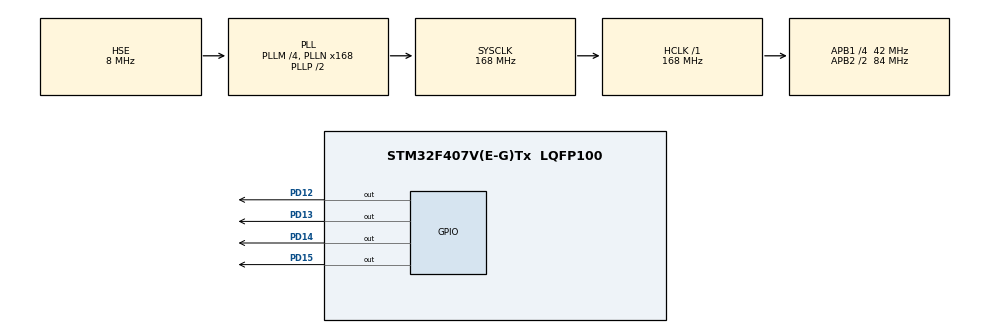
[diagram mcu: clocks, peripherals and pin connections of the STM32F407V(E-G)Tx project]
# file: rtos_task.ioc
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FREERTOS.INCLUDE_vTaskDelayUntil=1
FREERTOS.Tasks01=defaultTask,0,128,StartDefaultTask,Default,NULL,Dynamic,NULL,NULL
FREERTOS.configUSE_NEWLIB_REENTRANT=1
Mcu.Family=STM32F4
Mcu.Name=STM32F407V(E-G)Tx
Mcu.Package=LQFP100
NVIC.PriorityGroup=NVIC_PRIORITYGROUP_4
NVIC.TIM1_UP_TIM10_IRQn=true\:15\:0\:false\:false\:true\:false\:false\:true
NVIC.TimeBase=TIM1_UP_TIM10_IRQn
NVIC.TimeBaseIP=TIM1
PD12.Signal=GPIO_Output
PD13.Signal=GPIO_Output
PD14.Signal=GPIO_Output
PD15.Signal=GPIO_Output
PH0-OSC_IN.Mode=HSE-External-Oscillator
PH0-OSC_IN.Signal=RCC_OSC_IN
PH1-OSC_OUT.Mode=HSE-External-Oscillator
PH1-OSC_OUT.Signal=RCC_OSC_OUT
ProjectManager.HeapSize=0x200
ProjectManager.StackSize=0x400
ProjectManager.TargetToolchain=STM32CubeIDE
RCC.48MHZClocksFreq_Value=84000000
RCC.AHBFreq_Value=168000000
RCC.APB1CLKDivider=RCC_HCLK_DIV4
RCC.APB1Freq_Value=42000000
RCC.APB1TimFreq_Value=84000000
RCC.APB2CLKDivider=RCC_HCLK_DIV2
RCC.APB2Freq_Value=84000000
RCC.APB2TimFreq_Value=168000000
RCC.CortexFreq_Value=168000000
RCC.HCLKFreq_Value=168000000
RCC.HSE_VALUE=8000000
RCC.HSI_VALUE=16000000
RCC.LSE_VALUE=32768
RCC.PLLM=4
RCC.PLLN=168
RCC.PLLSourceVirtual=RCC_PLLSOURCE_HSE
RCC.SYSCLKFreq_VALUE=168000000
RCC.SYSCLKSource=RCC_SYSCLKSOURCE_PLLCLK
RCC.VCOOutputFreq_Value=336000000
VP_FREERTOS_VS_CMSIS_V1.Mode=CMSIS_V1
VP_SYS_VS_tim1.Mode=TIM1
board=custom

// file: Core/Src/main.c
/* USER CODE BEGIN Header */
/**
  ******************************************************************************
  * @file           : main.c
  * @brief          : Main program body
  ******************************************************************************
  * @attention
  *
  * <h2><center>&copy; Copyright (c) 2021 STMicroelectronics.
  * All rights reserved.</center></h2>
  *
  * This software component is licensed by ST under BSD 3-Clause license,
  * the "License"; You may not use this file except in compliance with the
  * License. You may obtain a copy of the License at:
  *                        opensource.org/licenses/BSD-3-Clause
  *
  ******************************************************************************
  */
/* USER CODE END Header */
#include "main.h"
#include "cmsis_os.h"

osThreadId defaultTaskHandle;

void SystemClock_Config(void);
static void MX_GPIO_Init(void);
void StartDefaultTask(void const * argument);

/* USER CODE BEGIN 0 */
int _write(int file,char*ptr, int len)
{
	int i=0;
	for (i=0;i<len;i++)
	{
		ITM_SendChar((*ptr++));
	}
	return len;
}

//define task handler
osThreadId Task2handler;

//define the entry function
void task2_init(void*argument);
uint8_t indx=0;
/* USER CODE END 0 */

int main(void)
{

  /* MCU Configuration--------------------------------------------------------*/

  /* Reset of all peripherals, Initializes the Flash interface and the Systick. */
  HAL_Init();

  /* Configure the system clock */
  SystemClock_Config();

  /* Initialize all configured peripherals */
  MX_GPIO_Init();
  /* USER CODE BEGIN 2 */
  printf("starting");
  /* USER CODE END 2 */

  /* Create the thread(s) */
  /* definition and creation of defaultTask */
  osThreadDef(defaultTask, StartDefaultTask, osPriorityNormal, 0, 128);
  defaultTaskHandle = osThreadCreate(osThread(defaultTask), NULL);

  /* USER CODE BEGIN RTOS_THREADS */
  /* add threads, ... */
  //define the thread
  osThreadDef(Task2,task2_init,osPriorityAboveNormal,0,128);
  //create thread and assign ID
  Task2handler = osThreadCreate(osThread(Task2), NULL);

  /* USER CODE END RTOS_THREADS */

  /* Start scheduler */
  osKernelStart();

  /* We should never get here as control is now taken by the scheduler */
  /* Infinite loop */
  while (1)
  {

    /* USER CODE BEGIN 3 */
//	  HAL_GPIO_TogglePin(GPIOD, GPIO_PIN_12);
//	  count++;
//	  printf("Hello world count = %d \n",count);
//	  HAL_Delay(1000);
  }
  /* USER CODE END 3 */
}

void SystemClock_Config(void)
{
  RCC_OscInitTypeDef RCC_OscInitStruct = {0};
  RCC_ClkInitTypeDef RCC_ClkInitStruct = {0};

  /** Configure the main internal regulator output voltage
  */
  __HAL_RCC_PWR_CLK_ENABLE();
  __HAL_PWR_VOLTAGESCALING_CONFIG(PWR_REGULATOR_VOLTAGE_SCALE1);
  /** Initializes the RCC Oscillators according to the specified parameters
  * in the RCC_OscInitTypeDef structure.
  */
  RCC_OscInitStruct.OscillatorType = RCC_OSCILLATORTYPE_HSE;
  RCC_OscInitStruct.HSEState = RCC_HSE_ON;
  RCC_OscInitStruct.PLL.PLLState = RCC_PLL_ON;
  RCC_OscInitStruct.PLL.PLLSource = RCC_PLLSOURCE_HSE;
  RCC_OscInitStruct.PLL.PLLM = 4;
  RCC_OscInitStruct.PLL.PLLN = 168;
  RCC_OscInitStruct.PLL.PLLP = RCC_PLLP_DIV2;
  RCC_OscInitStruct.PLL.PLLQ = 4;
  if (HAL_RCC_OscConfig(&RCC_OscInitStruct) != HAL_OK)
  {
    Error_Handler();
  }
  /** Initializes the CPU, AHB and APB buses clocks
  */
  RCC_ClkInitStruct.ClockType = RCC_CLOCKTYPE_HCLK|RCC_CLOCKTYPE_SYSCLK
                              |RCC_CLOCKTYPE_PCLK1|RCC_CLOCKTYPE_PCLK2;
  RCC_ClkInitStruct.SYSCLKSource = RCC_SYSCLKSOURCE_PLLCLK;
  RCC_ClkInitStruct.AHBCLKDivider = RCC_SYSCLK_DIV1;
  RCC_ClkInitStruct.APB1CLKDivider = RCC_HCLK_DIV4;
  RCC_ClkInitStruct.APB2CLKDivider = RCC_HCLK_DIV2;

  if (HAL_RCC_ClockConfig(&RCC_ClkInitStruct, FLASH_LATENCY_5) != HAL_OK)
  {
    Error_Handler();
  }
}

static void MX_GPIO_Init(void)
{
  GPIO_InitTypeDef GPIO_InitStruct = {0};

  /* GPIO Ports Clock Enable */
  __HAL_RCC_GPIOH_CLK_ENABLE();
  __HAL_RCC_GPIOD_CLK_ENABLE();

  /*Configure GPIO pin Output Level */
  HAL_GPIO_WritePin(GPIOD, GPIO_PIN_12|GPIO_PIN_13|GPIO_PIN_14|GPIO_PIN_15, GPIO_PIN_RESET);

  /*Configure GPIO pins : PD12 PD13 PD14 PD15 */
  GPIO_InitStruct.Pin = GPIO_PIN_12|GPIO_PIN_13|GPIO_PIN_14|GPIO_PIN_15;
  GPIO_InitStruct.Mode = GPIO_MODE_OUTPUT_PP;
  GPIO_InitStruct.Pull = GPIO_NOPULL;
  GPIO_InitStruct.Speed = GPIO_SPEED_FREQ_LOW;
  HAL_GPIO_Init(GPIOD, &GPIO_InitStruct);

}

/* USER CODE BEGIN 4 */
void task2_init(void*argument)
{
//	while(1)
//	{
//		printf("task2,indx = %d\n",indx++);
//		osDelay(2000);
////		if(indx==4)
////		{
////			printf("suspending DefaultTask\n");
////			osThreadSuspend(defaultTaskHandle);
////		}
////		if (indx==7)
////		{
////			printf("resuming DefaultTask\n");
////			osThreadResume(defaultTaskHandle);
////		}
////		if(indx==3)
////		{
////			printf("terminating myself\n ");
////			osThreadSuspend(Task2handler);
////		}
//		if(indx==3)
//		{
//			uint32_t PreviousWakeTime = osKernelSysTick();
//			osDelayUntil(&PreviousWakeTime, 3000);
//		}
//	}
	  for(;;)
	  {
		HAL_GPIO_TogglePin(GPIOD, GPIO_PIN_13);
		//printf("DefaultTask\n");
	    osDelay(1);
	  }
}
/* USER CODE END 4 */

void StartDefaultTask(void const * argument)
{
  /* USER CODE BEGIN 5 */
  /* Infinite loop */
  for(;;)
  {
	HAL_GPIO_TogglePin(GPIOD, GPIO_PIN_12);
	//printf("DefaultTask\n");
    osDelay(1);
  }
  /* USER CODE END 5 */
}

void HAL_TIM_PeriodElapsedCallback(TIM_HandleTypeDef *htim)
{
  if (htim->Instance == TIM1) {
    HAL_IncTick();
  }
}

void Error_Handler(void)
{
  __disable_irq();
  while (1)
  {
  }
}

/************************ (C) COPYRIGHT STMicroelectronics *****END OF FILE****/
